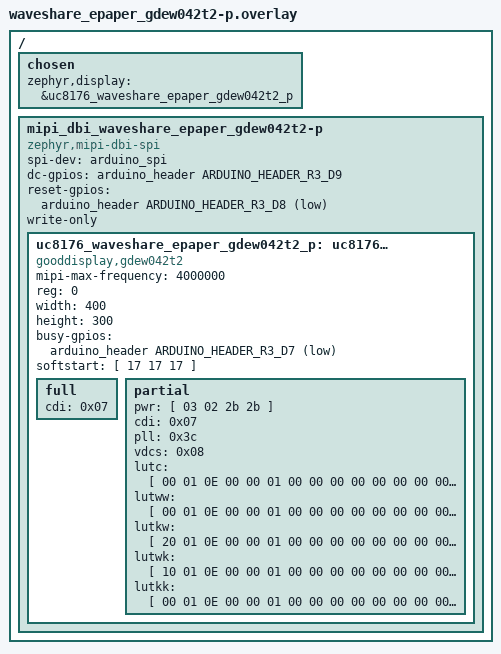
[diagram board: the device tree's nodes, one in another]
/*
 * Copyright (c) 2022 Andreas Sandberg
 *
 * SPDX-License-Identifier: Apache-2.0
 */

#include "waveshare_epaper_common.dtsi"
#include <zephyr/dt-bindings/gpio/arduino-header-r3.h>

/ {
	chosen {
		zephyr,display = &uc8176_waveshare_epaper_gdew042t2_p;
	};

	mipi_dbi_waveshare_epaper_gdew042t2-p {
		compatible = "zephyr,mipi-dbi-spi";
		spi-dev = <&arduino_spi>;
		dc-gpios = <&arduino_header ARDUINO_HEADER_R3_D9 GPIO_ACTIVE_HIGH>;
		reset-gpios = <&arduino_header ARDUINO_HEADER_R3_D8 GPIO_ACTIVE_LOW>;
		write-only;
		#address-cells = <1>;
		#size-cells = <0>;

		/*
		 * GoodDisplay GDEW042T2 with fast partial refresh. Based on
		 * configuration from GoodDisplay's Arduino example.
		 */
		uc8176_waveshare_epaper_gdew042t2_p: uc8176@0 {
			compatible = "gooddisplay,gdew042t2", "ultrachip,uc8176";
			mipi-max-frequency = <4000000>;
			reg = <0>;
			width = <400>;
			height = <300>;
			busy-gpios = <&arduino_header ARDUINO_HEADER_R3_D7 GPIO_ACTIVE_LOW>;

			softstart = [ 17 17 17 ];

			full {
				cdi = <0x07>;
			};

			partial {
				pwr = [ 03 02 2b 2b ];
				cdi = <0x07>;
				pll = <0x3c>;
				vdcs = <0x08>;

				lutc = [
					00 01 0E 00 00 01
					00 00 00 00 00 00
					00 00 00 00 00 00
					00 00 00 00 00 00
					00 00 00 00 00 00
					00 00 00 00 00 00
					00 00 00 00 00 00
					00 00
				];

				lutww = [
					00 01 0E 00 00 01
					00 00 00 00 00 00
					00 00 00 00 00 00
					00 00 00 00 00 00
					00 00 00 00 00 00
					00 00 00 00 00 00
					00 00 00 00 00 00
				];

				lutkw = [
					20 01 0E 00 00 01
					00 00 00 00 00 00
					00 00 00 00 00 00
					00 00 00 00 00 00
					00 00 00 00 00 00
					00 00 00 00 00 00
					00 00 00 00 00 00
				];

				lutwk = [
					10 01 0E 00 00 01
					00 00 00 00 00 00
					00 00 00 00 00 00
					00 00 00 00 00 00
					00 00 00 00 00 00
					00 00 00 00 00 00
					00 00 00 00 00 00
				];

				lutkk = [
					00 01 0E 00 00 01
					00 00 00 00 00 00
					00 00 00 00 00 00
					00 00 00 00 00 00
					00 00 00 00 00 00
					00 00 00 00 00 00
					00 00 00 00 00 00
				];
			};
		};
	};
};
